VERSION ""

BS_:

BU_:

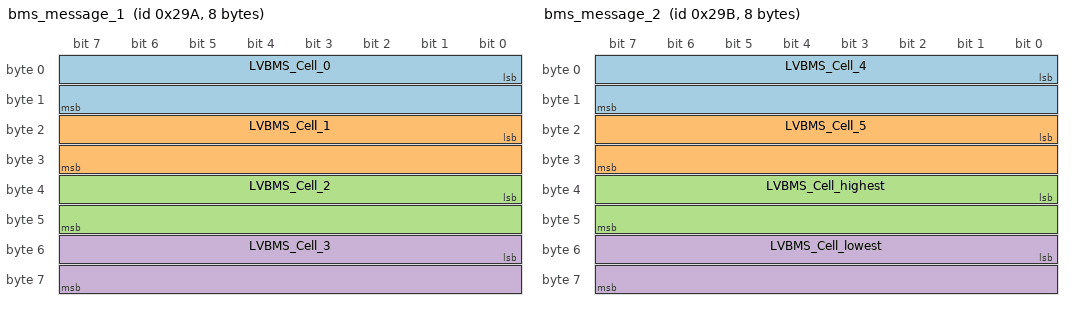
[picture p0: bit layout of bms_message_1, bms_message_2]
BO_ 666 bms_message_1: 8 LVBMS
SG_ LVBMS_Cell_0 : 0|16@1+ (0.001,0) [0|6.5535] "V" LVBMS
SG_ LVBMS_Cell_1 : 16|16@1+ (0.001,0) [0|6.5535] "V" LVBMS
SG_ LVBMS_Cell_2 : 32|16@1+ (0.001,0) [0|6.5535] "V" LVBMS
SG_ LVBMS_Cell_3 : 48|16@1+ (0.001,0) [0|6.5535] "V" LVBMS

BO_ 667 bms_message_2: 8 LVBMS
SG_ LVBMS_Cell_4 : 0|16@1+ (0.001,0) [0|6.5535] "V" LVBMS
SG_ LVBMS_Cell_5 : 16|16@1+ (0.001,0) [0|6.5535] "V" LVBMS
SG_ LVBMS_Cell_highest : 32|16@1+ (0.001,0) [0|6.5535] "V" LVBMS
SG_ LVBMS_Cell_lowest : 48|16@1+ (0.001,0) [0|6.5535] "V" LVBMS

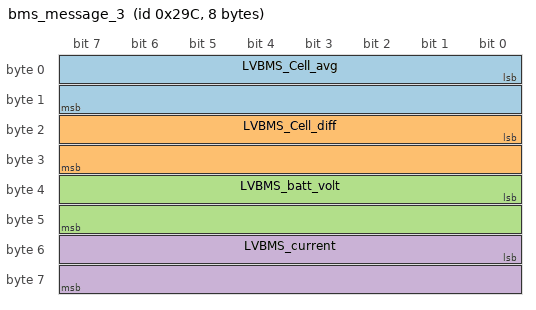
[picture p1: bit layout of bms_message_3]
BO_ 668 bms_message_3: 8 LVBMS
SG_ LVBMS_Cell_avg : 0|16@1+ (0.001,0) [0|6.5535] "V" LVBMS
SG_ LVBMS_Cell_diff : 16|16@1+ (0.001,0) [0|6.5535] "V" LVBMS
SG_ LVBMS_batt_volt : 32|16@1+ (0.001,0) [0|25] "V" LVBMS
SG_ LVBMS_current : 48|16@1+ (0.001,0) [0|8] "A" LVBMS

BO_ 669 bms_message_4: 8 LVBMS
SG_ LVBMS_Thermistor : 0|16@1+ (0.001,0) [0|6.5535] "C" LVBMS
SG_ LVBMS_Short_Circuit : 8|1@1- (1,0) [0|1] " " LVBMS
SG_ LVBMS_Over_Load : 9|1@1- (1,0) [0|1] " " LVBMS
SG_ LVBMS_Over_Voltage : 10|1@1- (1,0) [0|1] " " LVBMS
SG_ LVBMS_Under_Voltage : 11|1@1- (1,0) [0|1] " " LVBMS
SG_ LVBMS_Over_Temp : 16|1@1- (1,0) [0|1] " " LVBMS
SG_ LVBMS_Power_Good : 17|1@1- (1,0) [0|1] " " LVBMS
SG_ LVBMS_Discharging : 18|1@1- (1,0) [0|1] " " LVBMS
SG_ LVBMS_Charging : 19|1@1- (1,0) [0|1] " " LVBMS
SG_ LVBMS_Balancing_Cell_0 : 20|1@1- (1,0) [0|1] " " LVBMS
SG_ LVBMS_Balancing_Cell_1 : 21|1@1- (1,0) [0|1] " " LVBMS
SG_ LVBMS_Balancing_Cell_3 : 22|1@1- (1,0) [0|1] " " LVBMS
SG_ LVBMS_Balancing_Cell_4 : 23|1@1- (1,0) [0|1] " " LVBMS
SG_ LVBMS_Balancing_Cell_5 : 24|1@1- (1,0) [0|1] " " LVBMS
SG_ LVBMS_batt_state_standby : 25|1@1- (1,0) [0|1] " " LVBMS
SG_ LVBMS_batt_state_charing : 26|1@1- (1,0) [0|1] " " LVBMS
SG_ LVBMS_batt_state_discharging : 27|1@1- (1,0) [0|1] " " LVBMS
SG_ LVBMS_batt_state_fault : 28|1@1- (1,0) [0|1] " " LVBMS
SG_ LVBMS_batt_state_charging_and_balancing : 29|1@1- (1,0) [0|1] " " LVBMS
SG_ LVBMS_batt_state_balancing : 30|1@1- (1,0) [0|1] " " LVBMS
SG_ LVBMS_xx : 31|1@1- (1,0) [0|1] " " LVBMS
SG_ LVBMS_xxx : 32|1@1- (1,0) [0|1] " " LVBMS
